# LPC5411x register map
File version: 0.3
CPU: CM4 r0p0, little endian, MPU, FPU, 3 interrupt priority bits
Registers are 32-bit, read-write, reset 0x0 unless marked. A register's access mark holds for its fields unless they carry their own. Offsets are from the block's base; [hi:lo] are bit positions; {n}, {i} and the like mark numbered series.

## SCT0 — State Configurable Timer/PWM 0
Base 0x40085000
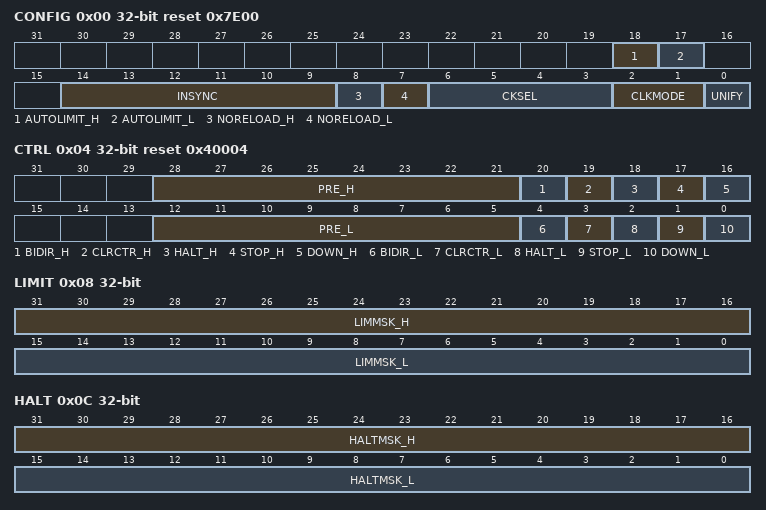
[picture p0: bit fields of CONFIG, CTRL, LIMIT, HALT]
0x00 CONFIG reset 0x7E00 — SCT configuration register
  [18] AUTOLIMIT_H — A one in this bit will cause a match on match register 0 to be treated as a de-facto LIMIT condition without the need to define an associated event. As with any LIMIT event, this automatic limit causes the counter to be cleared to zero in uni-directional mode or to change the direction of count in bi-directional mode. Software can write to set or clear this bit at any time. This bit is not used when the UNIFY bit is set.
  [17] AUTOLIMIT_L — A one in this bit causes a match on match register 0 to be treated as a de-facto LIMIT condition without the need to define an associated event. As with any LIMIT event, this automatic limit causes the counter to be cleared to zero in uni-directional mode or to change the direction of count in bi-directional mode. Software can write to set or clear this bit at any time. This bit applies to both the higher and lower registers when the UNIFY bit is set.
  [14:9] INSYNC — Synchronization for input n (bit 9 = input 0, bit 10 = input 1,..., bit 14 = input 5). A 1 in one of these bits subjects the corresponding input to synchronization to the SCT clock, before it is used to create an event. If an input is synchronous to the SCT clock, keep its bit 0 for faster response. When the CLKMODE field is 1x, the bit in this field, corresponding to the input selected by the CKSEL field, is not used.
  [8] NORELOAD_H — A 1 in this bit prevents the higher match registers from being reloaded from their respective reload registers. Software can write to set or clear this bit at any time. This bit is not used when the UNIFY bit is set.
  [7] NORELOAD_L — A 1 in this bit prevents the lower match registers from being reloaded from their respective reload registers. Software can write to set or clear this bit at any time. This bit applies to both the higher and lower registers when the UNIFY bit is set.
  [6:3] CKSEL — SCT clock select
    0=INPUT_0_RISING_EDGES; 1=INPUT_0_FALLING_EDGE (Input 0 falling edges.); 2=INPUT_1_RISING_EDGES; 3=INPUT_1_FALLING_EDGE (Input 1 falling edges.); 4=INPUT_2_RISING_EDGES; 5=INPUT_2_FALLING_EDGE (Input 2 falling edges.); 6=INPUT_3_RISING_EDGES; 7=INPUT_3_FALLING_EDGE (Input 3 falling edges.); 8=INPUT_4_RISING_EDGES; 9=INPUT_4_FALLING_EDGE (Input 4 falling edges.); 10=INPUT_5_RISING_EDGES; 11=INPUT_5_FALLING_EDGE (Input 5 falling edges.); 12=INPUT_6_RISING_EDGES; 13=INPUT_6_FALLING_EDGE (Input 6 falling edges.); 14=INPUT_7_RISING_EDGES; 15=INPUT_7_FALLING_EDGE (Input 7 falling edges.)
  [2:1] CLKMODE — SCT clock mode
    0=SYSTEM_CLOCK (System clock. The system clock clocks the SCT and prescalers.); 1=PRESCALED_SYSTEM_CLO (Prescaled system clock. The SCT clock is the system clock, but the prescalers are enabled to count only when sampling of the input selected by the CKSEL field finds the selected edge. The minimum pulse width on the clock input is 1 bus clock period. This mode is the high-performance sampled-clock mode.); 2=SCT_INPUT (SCT input. The input selected by CKSEL clocks the SCT and prescalers. The input is synchronized to the system clock and possibly inverted. The minimum pulse width on the clock input is 1 bus clock period. This mode is the low-power sampled-clock mode.); 3=PRESCALED_SCT_INPUT (Prescaled SCT input. The SCT and prescalers are clocked by the input edge selected by the CKSEL field. In this mode, most of the SCT is clocked by the (selected polarity of the) input. The outputs are switched synchronously to the input clock. The input clock rate must be at least half the system clock rate and can be the same or faster than the system clock.)
  [0] UNIFY — SCT operation
    0=DUAL_COUNTER (Dual counter. The SCT operates as two 16-bit counters named L and H.); 1=UNIFIED_COUNTER (Unified counter. The SCT operates as a unified 32-bit counter.)
0x04 CTRL reset 0x40004 — SCT control register
  [28:21] PRE_H — Specifies the factor by which the SCT clock is prescaled to produce the H counter clock. The counter clock is clocked at the rate of the SCT clock divided by PRELH+1. Clear the counter (by writing a 1 to the CLRCTR bit) whenever changing the PRE value.
  [20] BIDIR_H — Direction select
    0=UNIDIRECTIONAL (Unidirectional. The H counter counts up to its limit condition, then is cleared to zero.); 1=BIDIRECTIONAL (Bidirectional. The H counter counts up to its limit, then counts down to a limit condition or to 0.)
  [19] CLRCTR_H — Writing a 1 to this bit clears the H counter. This bit always reads as 0.
  [18] HALT_H — When this bit is 1, the H counter does not run and no events can occur. A reset sets this bit. When the HALT_H bit is one, the STOP_H bit is cleared. In order to remove the halt condition and keep the SCT in the stop condition (not running), the halt and stop condition can be changed with one single write to this register. Once set, this bit can only be cleared by software to restore counter operation.
  [17] STOP_H — When this bit is 1 and HALT is 0, the H counter does not run but I/O events related to the counter can occur. If such an event matches the mask in the Start register, this bit is cleared and counting resumes.
  [16] DOWN_H — This bit is 1 when the H counter is counting down. Hardware sets this bit when the counter limit is reached and BIDIR is 1. Hardware clears this bit when the counter reaches 0 or when the counter is counting down and a limit condition occurs.
  [12:5] PRE_L — Specifies the factor by which the SCT clock is prescaled to produce the L or unified counter clock. The counter clock is clocked at the rate of the SCT clock divided by PRE_L+1. Clear the counter (by writing a 1 to the CLRCTR bit) whenever changing the PRE value.
  [4] BIDIR_L — L or unified counter direction select
    0=UNIDIRECTIONAL (Unidirectional. The counter counts up to its limit condition, then is cleared to zero.); 1=BIDIRECTIONAL (Bidirectional. The counter counts up to its limit, then counts down to a limit condition or to 0.)
  [3] CLRCTR_L — Writing a 1 to this bit clears the L or unified counter. This bit always reads as 0.
  [2] HALT_L — When this bit is 1, the L or unified counter does not run and no events can occur. A reset sets this bit. When the HALT_L bit is one, the STOP_L bit is cleared. In order to remove the halt condition and keep the SCT in the stop condition (not running), the halt and stop condition can be changed with one single write to this register. Once set, only software can clear this bit to restore counter operation.
  [1] STOP_L — When this bit is 1 and HALT is 0, the L or unified counter does not run but I/O events related to the counter can occur. If such an event matches the mask in the Start register, this bit is cleared and counting resumes.
  [0] DOWN_L — This bit is 1 when the L or unified counter is counting down. Hardware sets this bit when the counter limit is reached and BIDIR is 1. Hardware clears this bit when the counter reaches 0 or when the counter is counting down and a limit condition occurs.
0x08 LIMIT — SCT limit register
  [31:16] LIMMSK_H — If bit n is one, event n is used as a counter limit event for the H counter (event 0 = bit 16, event 1 = bit 17, etc. The number of bits = number of events in this SCT.
  [15:0] LIMMSK_L — If bit n is one, event n is used as a counter limit event for the L or unified counter (event 0 = bit 0, event 1 = bit 1, etc. The number of bits = number of events in this SCT.
0x0C HALT — SCT halt condition register
  [31:16] HALTMSK_H — If bit n is one, event n sets the HALT_H bit in the CTRL register (event 0 = bit 16, event 1 = bit 17, etc. The number of bits = number of events in this SCT.
  [15:0] HALTMSK_L — If bit n is one, event n sets the HALT_L bit in the CTRL register (event 0 = bit 0, event 1 = bit 1, etc. The number of bits = number of events in this SCT.
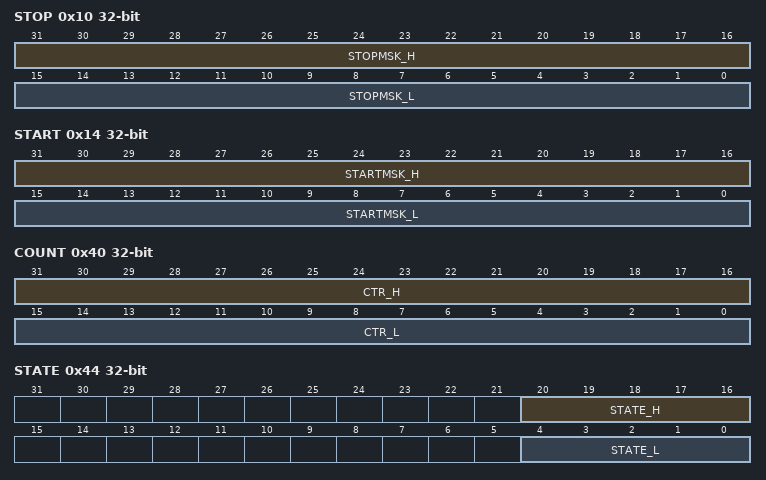
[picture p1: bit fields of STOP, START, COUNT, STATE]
0x10 STOP — SCT stop condition register
  [31:16] STOPMSK_H — If bit n is one, event n sets the STOP_H bit in the CTRL register (event 0 = bit 16, event 1 = bit 17, etc. The number of bits = number of events in this SCT.
  [15:0] STOPMSK_L — If bit n is one, event n sets the STOP_L bit in the CTRL register (event 0 = bit 0, event 1 = bit 1, etc. The number of bits = number of events in this SCT.
0x14 START — SCT start condition register
  [31:16] STARTMSK_H — If bit n is one, event n clears the STOP_H bit in the CTRL register (event 0 = bit 16, event 1 = bit 17, etc. The number of bits = number of events in this SCT.
  [15:0] STARTMSK_L — If bit n is one, event n clears the STOP_L bit in the CTRL register (event 0 = bit 0, event 1 = bit 1, etc. The number of bits = number of events in this SCT.
0x40 COUNT — SCT counter register
  [31:16] CTR_H — When UNIFY = 0, read or write the 16-bit H counter value. When UNIFY = 1, read or write the upper 16 bits of the 32-bit unified counter.
  [15:0] CTR_L — When UNIFY = 0, read or write the 16-bit L counter value. When UNIFY = 1, read or write the lower 16 bits of the 32-bit unified counter.
0x44 STATE — SCT state register
  [20:16] STATE_H — State variable.
  [4:0] STATE_L — State variable.
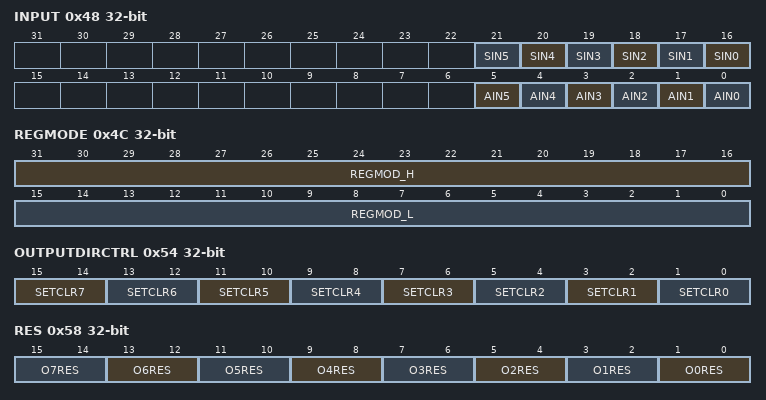
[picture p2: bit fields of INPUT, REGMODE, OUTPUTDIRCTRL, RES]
0x48 INPUT ro — SCT input register
  [n+16] SIN{n} (n=0..5) — Input {n} state.
  [n] AIN{n} (n=1..5) — Input {n} state. Direct read.
  [0] AIN0 — Input 0 state.Direct read.
0x4C REGMODE — SCT match/capture registers mode register
  [31:16] REGMOD_H — Each bit controls one pair of match/capture registers (register 0 = bit 16, register 1 = bit 17, etc. 0 = registers operate as match registers. 1 = registers operate as capture registers.
  [15:0] REGMOD_L — Each bit controls one pair of match/capture registers (register 0 = bit 0, register 1 = bit 1,..., etc. 0 = registers operate as match registers. 1 = registers operate as capture registers.
0x50 OUTPUT — SCT output register
  [7:0] OUT — Writing a 1 to bit n makes the corresponding output HIGH. 0 makes the corresponding output LOW (output 0 = bit 0, output 1 = bit 1, etc.
0x54 OUTPUTDIRCTRL — SCT output counter direction control register
  [2n+1:2n] SETCLR{n} (n=1..7) — Set/clear operation on output {n}. See description of bit 0.
  [1:0] SETCLR0 — Set/clear operation on output 0. Value 0x3 is reserved. Do not program this value.
    0=INDEPENDENT (Independent. Set and clear do not depend on any counter.); 1=L_REVERSED (L-Reversed. Set and clear are reversed when counter L or the unified counter is counting down.); 2=H_REVERSED (H-Reversed. Set and clear are reversed when counter H is counting down. Do not use if UNIFY = 1.)
0x58 RES — SCT conflict resolution register
  [2n+1:2n] O{n}RES (n=0..7) — Effect of simultaneous set and clear on output {n}.
    0=NO_CHANGE; 1=SET (Set. Set output (or clear based on the SETCLR{n} field).); 2=CLEAR (Clear. Clear output (or set based on the SETCLR{n} field).); 3=TOGGLE_OUTPUT
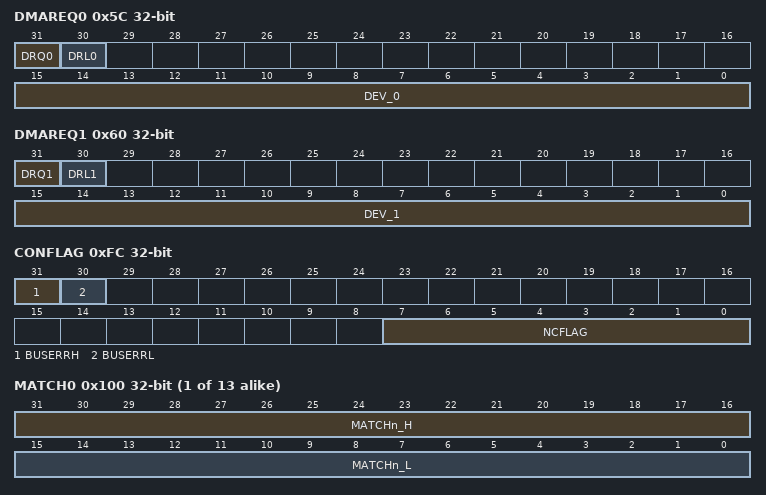
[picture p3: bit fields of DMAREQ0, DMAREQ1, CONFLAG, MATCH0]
0x5C DMAREQ0 — SCT DMA request 0 register
  [31] DRQ0 — This read-only bit indicates the state of DMA Request 0
  [30] DRL0 — A 1 in this bit makes the SCT set DMA request 0 when it loads the Match_L/Unified registers from the Reload_L/Unified registers.
  [15:0] DEV_0 — If bit n is one, event n sets DMA request 0 (event 0 = bit 0, event 1 = bit 1, etc. The number of bits = number of events in this SCT.
0x60 DMAREQ1 — SCT DMA request 1 register
  [31] DRQ1 — This read-only bit indicates the state of DMA Request 1.
  [30] DRL1 — A 1 in this bit makes the SCT set DMA request 1 when it loads the Match L/Unified registers from the Reload L/Unified registers.
  [15:0] DEV_1 — If bit n is one, event n sets DMA request 1 (event 0 = bit 0, event 1 = bit 1, etc. The number of bits = number of events in this SCT.
0xF0 EVEN — SCT event enable register
  [15:0] IEN — The SCT requests interrupt when bit n of this register and the event flag register are both one (event 0 = bit 0, event 1 = bit 1, etc.
0xF4 EVFLAG — SCT event flag register
  [15:0] FLAG — Bit n is one if event n has occurred since reset or a 1 was last written to this bit (event 0 = bit 0, event 1 = bit 1,etc. The number of bits = number of events in this SCT.
0xF8 CONEN — SCT conflict enable register
  [7:0] NCEN — The SCT requests an interrupt when bit n of this register and the SCT conflict flag register are both one (output 0 = bit 0, output 1 = bit 1, etc.
0xFC CONFLAG — SCT conflict flag register
  [31] BUSERRH — The most recent bus error from this SCT involved writing CTR H, STATE H, MATCH H, or the Output register when the H counter was not halted.
  [30] BUSERRL — The most recent bus error from this SCT involved writing CTR L/Unified, STATE L/Unified, MATCH L/Unified, or the Output register when the L/U counter was not halted. A word write to certain L and H registers can be half successful and half unsuccessful.
  [7:0] NCFLAG — Bit n is one if a no-change conflict event occurred on output n since reset or a 1 was last written to this bit (output 0 = bit 0, output 1 = bit 1, etc.
{0x100+4i} MATCH{i} (i=0..12) — SCT match value register of match channels 0 to 12; REGMOD0 to REGMODE12 = 0
  [31:16] MATCHn_H — When UNIFY = 0, read or write the 16-bit value to be compared to the H counter. When UNIFY = 1, read or write the upper 16 bits of the 32-bit value to be compared to the unified counter.
  [15:0] MATCHn_L — When UNIFY = 0, read or write the 16-bit value to be compared to the L counter. When UNIFY = 1, read or write the lower 16 bits of the 32-bit value to be compared to the unified counter.
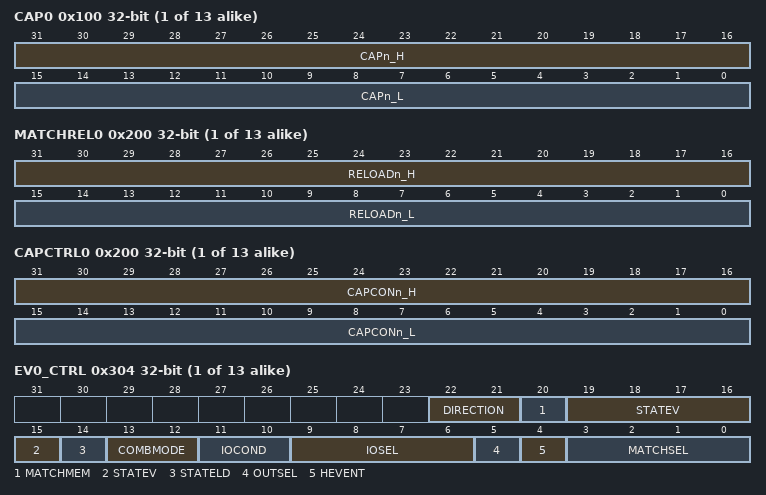
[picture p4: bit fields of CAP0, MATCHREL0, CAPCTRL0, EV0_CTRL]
{0x100+4i} CAP{i} (i=0..12) ro (alternate view of MATCH{i}) — SCT capture register of capture channel 0 to 12; REGMOD0 to REGMODE12 = 1
  [31:16] CAPn_H — When UNIFY = 0, read the 16-bit counter value at which this register was last captured. When UNIFY = 1, read the upper 16 bits of the 32-bit value at which this register was last captured.
  [15:0] CAPn_L — When UNIFY = 0, read the 16-bit counter value at which this register was last captured. When UNIFY = 1, read the lower 16 bits of the 32-bit value at which this register was last captured.
{0x200+4i} MATCHREL{i} (i=0..12) — SCT match reload value register 0 to 12; REGMOD0 = 0 to REGMODE12 = 0
  [31:16] RELOADn_H — When UNIFY = 0, read or write the 16-bit to be loaded into the MATCHn_H register. When UNIFY = 1, read or write the upper 16 bits of the 32-bit value to be loaded into the MATCHn register.
  [15:0] RELOADn_L — When UNIFY = 0, read or write the 16-bit value to be loaded into the MATCHn_L register. When UNIFY = 1, read or write the lower 16 bits of the 32-bit value to be loaded into the MATCHn register.
{0x200+4i} CAPCTRL{i} (i=0..12) (alternate view of MATCHREL{i}) — SCT capture control register 0 to 12; REGMOD0 = 1 to REGMODE12 = 1
  [31:16] CAPCONn_H — If bit m is one, event m causes the CAPn_H (UNIFY = 0) register to be loaded (event 0 = bit 16, event 1 = bit 17, etc. The number of bits = number of events in this SCT.
  [15:0] CAPCONn_L — If bit m is one, event m causes the CAPn_L (UNIFY = 0) or the CAPn (UNIFY = 1) register to be loaded (event 0 = bit 0, event 1 = bit 1, etc. The number of bits = number of events in this SCT.
{0x300+8i} EV{i}_STATE (i=0..12) — SCT event state register 0
  [12:0] STATEMSKn — If bit m is one, event n happens in state m of the counter selected by the HEVENT bit (m = state number; state 0 = bit 0, state 1= bit 1, etc. The number of bits = number of events in this SCT.
{0x304+8i} EV{i}_CTRL (i=0..12) — SCT event control register 0
  [22:21] DIRECTION — Direction qualifier for event generation. This field only applies when the counters are operating in BIDIR mode. If BIDIR = 0, the SCT ignores this field. Value 0x3 is reserved.
    0=DIRECTION_INDEPENDEN (Direction independent. This event is triggered regardless of the count direction.); 1=COUNTING_UP (Counting up. This event is triggered only during up-counting when BIDIR = 1.); 2=COUNTING_DOWN (Counting down. This event is triggered only during down-counting when BIDIR = 1.)
  [20] MATCHMEM — If this bit is one and the COMBMODE field specifies a match component to the triggering of this event, then a match is considered to be active whenever the counter value is GREATER THAN OR EQUAL TO the value specified in the match register when counting up, LESS THEN OR EQUAL TO the match value when counting down. If this bit is zero, a match is only be active during the cycle when the counter is equal to the match value.
  [19:15] STATEV — This value is loaded into or added to the state selected by HEVENT, depending on STATELD, when this event is the highest-numbered event occurring for that state. If STATELD and STATEV are both zero, there is no change to the STATE value.
  [14] STATELD — This bit controls how the STATEV value modifies the state selected by HEVENT when this event is the highest-numbered event occurring for that state.
    0=ADD (Add. STATEV value is added into STATE (the carry-out is ignored).); 1=LOAD (Load. STATEV value is loaded into STATE.)
  [13:12] COMBMODE — Selects how the specified match and I/O condition are used and combined.
    0=OR (OR. The event occurs when either the specified match or I/O condition occurs.); 1=MATCH (MATCH. Uses the specified match only.); 2=IO (IO. Uses the specified I/O condition only.); 3=AND (AND. The event occurs when the specified match and I/O condition occur simultaneously.)
  [11:10] IOCOND — Selects the I/O condition for event n. (The detection of edges on outputs lags the conditions that switch the outputs by one SCT clock). In order to guarantee proper edge/state detection, an input must have a minimum pulse width of at least one SCT clock period .
    0=LOW; 1=RISE; 2=FALL; 3=HIGH
  [9:6] IOSEL — Selects the input or output signal associated with this event (if any). Do not select an input in this register, if CLKMODE is 1x. In this case the clock input is an implicit ingredient of every event.
  [5] OUTSEL — Input/output select
    0=INPUT (Input. Selects the input selected by IOSEL.); 1=OUTPUT (Output. Selects the output selected by IOSEL.)
  [4] HEVENT — Select L/H counter. Do not set this bit if UNIFY = 1.
    0=L_COUNTER (L counter. Selects the L state and the L match register selected by MATCHSEL.); 1=H_COUNTER (H counter. Selects the H state and the H match register selected by MATCHSEL.)
  [3:0] MATCHSEL — Selects the Match register associated with this event (if any). A match can occur only when the counter selected by the HEVENT bit is running.
{0x500+8i} OUT{i}_SET (i=0..7) — SCT output 0 set register
  [15:0] SET — A 1 in bit m selects event m to set output n (or clear it if SETCLRn = 0x1 or 0x2) event 0 = bit 0, event 1 = bit 1, etc. The number of bits = number of events in this SCT.
{0x504+8i} OUT{i}_CLR (i=0..7) — SCT output 0 clear register
  [15:0] CLR — A 1 in bit m selects event m to clear output n (or set it if SETCLRn = 0x1 or 0x2) event 0 = bit 0, event 1 = bit 1, etc. The number of bits = number of events in this SCT.
